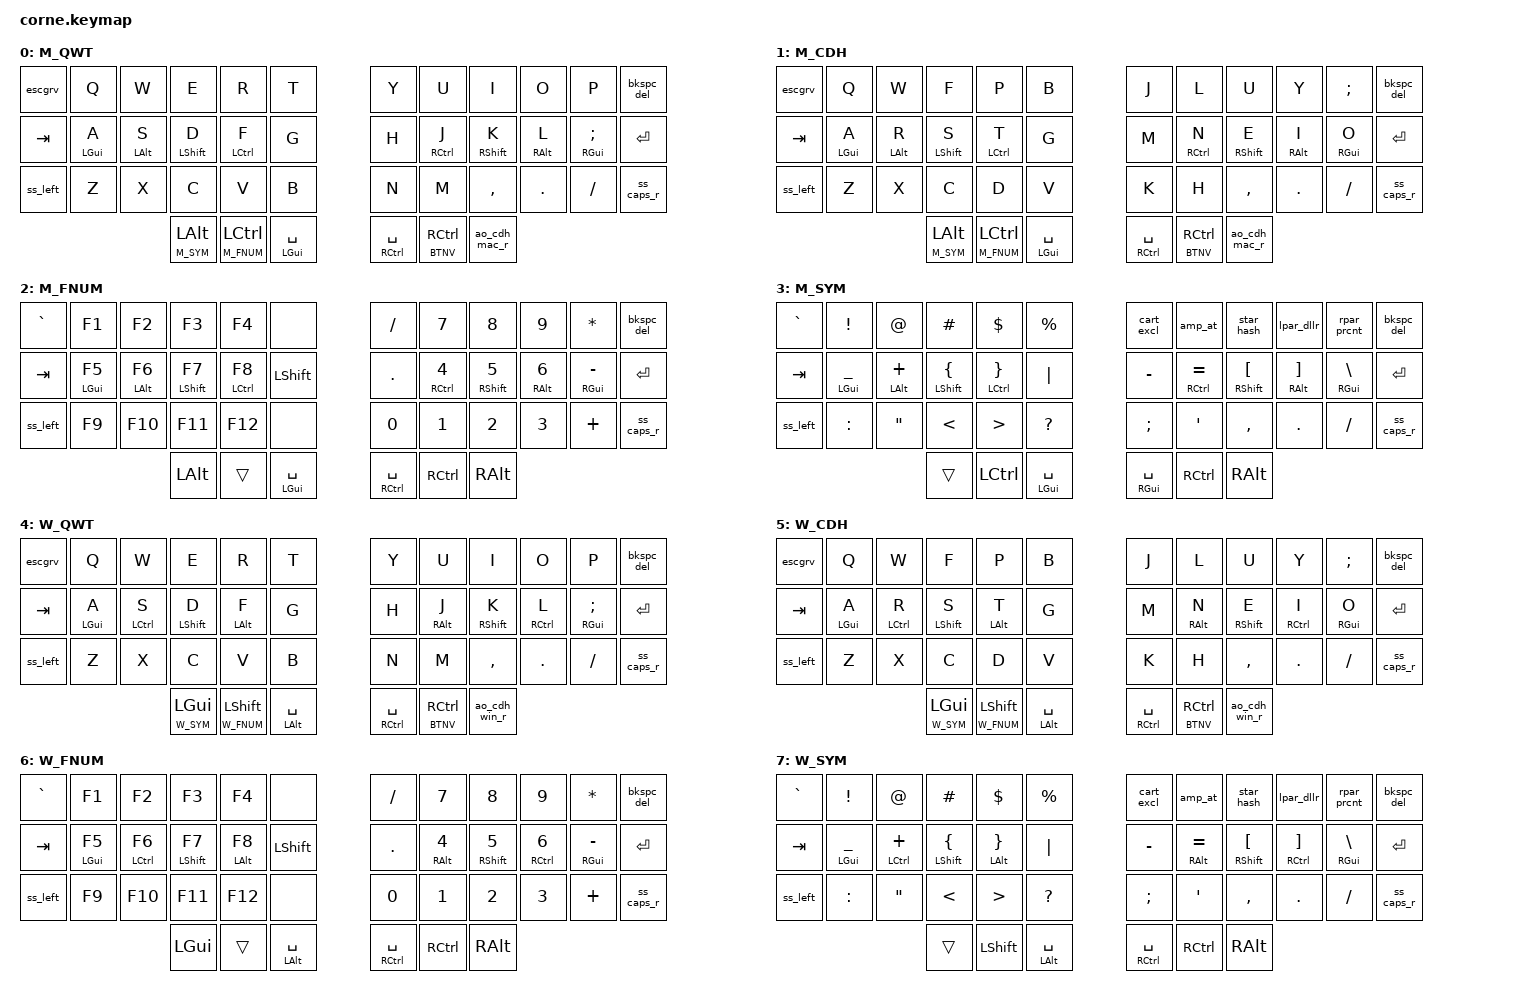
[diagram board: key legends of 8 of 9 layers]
/*
 * Copyright (c) 2020 The ZMK Contributors
 *
 * SPDX-License-Identifier: MIT
 */

// INCLUDES - START  ***********************************************************
// ZMK Core Includes
#include <behaviors.dtsi>
#include <dt-bindings/zmk/keys.h>
#include <dt-bindings/zmk/bt.h>
#include <dt-bindings/zmk/outputs.h>

// JINIUS Includes
// Key position includes
#include "corne_42keys.h"
// INCLUDES - ENDS *************************************************************

// DEFINES - START *************************************************************
// DEFINES LAYERS - START ******************************************************
// Layer shotcuts defined for easier identification.
// The order must match in which they are defined below.
#define M_QWT 0
#define M_CDH 1
#define M_FNUM 2
#define M_SYM 3
#define W_QWT 4
#define W_CDH 5
#define W_FNUM 6
#define W_SYM 7
#define BTNV 8
// DEFINES LAYERS - ENDS *******************************************************
// DEFINES BLUETOOTH PROFILE SELECTION - START *********************************
#define BTP0 BT_SEL 0
#define BTP1 BT_SEL 1
#define BTP2 BT_SEL 2
#define BTP3 BT_SEL 3
#define BTP4 BT_SEL 4
// DEFINES BLUETOOTH PROFILE SELECTION - ENDS **********************************

// DEFINES KEY TYPE ALIAS - START **********************************************
#define XXX &none   // To trap the key event in a given layer
#define ___ &trans  // To pass the key event to the next active layer
// DEFINES KEY TYPE ALIAS - ENDS ***********************************************

// DEFINES GLOBAL SETTINGS - START *********************************************
#define TAPPING_TERM_MS 280
#define QUICK_TAP_MS 175
#define REQUIRE_PRIOR_IDLE_MS 125
// DEFINES GLOBAL SETTINGS - ENDS **********************************************

// DEFINES KEY CONFIGURATION SETTINGS - START **********************************
&sk {  // sticky-key config
    release-after-ms = <900>;  // release after 0.6s
    quick-release;             // no double capitalization when rolling keys
};

&sl {  // sticky-layer config
    ignore-modifiers;          // allow chording sticky mods & layers
};

&lt {  // layer-tap config
    flavor = "balanced";
    tapping-term-ms = <200>;
    quick-tap-ms = <QUICK_TAP_MS>;
};
// DEFINES KEY CONFIGURATION SETTINGS - ENDS ***********************************

// DEFINES COMBINATION KEYS FOR HOMEROW MODS - START ***************************
#define LEFT_HAND_KEYS LT0 LT1 LT2 LT3 LT4 LT5 LM0 LM1 LM2 LM3 LM4 LM5 LB0 LB1 LB2 LB3 LB4 LB5
#define RIGHT_HAND_KEYS RT0 RT1 RT2 RT3 RT4 RT5 RM0 RM1 RM2 RM3 RM4 RM5 RB0 RB1 RB2 RB3 RB4 RB5
#define THUMB_KEYS LH0 LH1 LH2 RH0 RH1 RH2
// DEFINES COMBINATION KEYS FOR HOMEROW MODS - ENDS ****************************

// DEFINES - ENDS **************************************************************

// ROOT DEVICETREE NODE - START ************************************************
/ {

// BEHAVIOR - START ************************************************************
  // BEHAVIOR DEFINITIONS - START **********************************************
  // Homerow mod definition for left hand keys
  behaviors {
    /***********************************************
     **  Homerow mod for left split keyboard
     **  as explained here: https://github.com/urob/zmk-config#timeless-homerow-mods
     **  This is a expanded version of the same functionality along with the timings
     ***********************************************/
    hml: homerow_mod_left {
      compatible = "zmk,behavior-hold-tap";
      #binding-cells = <2>;
      bindings = <&kp>, <&kp>;
      flavor = "balanced";
      tapping-term-ms = <TAPPING_TERM_MS>;
      quick-tap-ms = <QUICK_TAP_MS>;
      require-prior-idle-ms = <REQUIRE_PRIOR_IDLE_MS>;
      hold-trigger-key-positions = <RIGHT_HAND_KEYS THUMB_KEYS>;
    };
    /***********************************************
     **  Homerow mod for right split keyboard
     **  as explained here: https://github.com/urob/zmk-config#timeless-homerow-mods
     **  This is a expanded version of the same functionality along with the timings
     ***********************************************/
    hmr: homerow_mod_right {
      compatible = "zmk,behavior-hold-tap";
      #binding-cells = <2>;
      bindings = <&kp>, <&kp>;
      flavor = "balanced";
      tapping-term-ms = <TAPPING_TERM_MS>;
      quick-tap-ms = <QUICK_TAP_MS>;
      require-prior-idle-ms = <REQUIRE_PRIOR_IDLE_MS>;
      hold-trigger-key-positions = <LEFT_HAND_KEYS THUMB_KEYS>;
    };
    /***********************************************
     ** Momentary Sticky Mod: Momentary layer on hold and tap to sticky modifier
     ** Holding the key will switch to the layer, taping will configure the sticky modifier
     **   hold: momentary layer
     **   tap: sticky modifier
     ***********************************************/
    mosm: momentary_sticky_mod {
      compatible = "zmk,behavior-hold-tap";
      #binding-cells = <2>;
      bindings = <&mo>, <&sk>;
      flavor = "balanced";
      tapping-term-ms = <TAPPING_TERM_MS>;
      quick-tap-ms = <QUICK_TAP_MS>;
      require-prior-idle-ms = <REQUIRE_PRIOR_IDLE_MS>;
      hold-trigger-on-release;
    };
    /***********************************************
     ** Thumb Mod Tap: Hold to modifier, Tap to key press
     ** Holding the key will activate the modifier and tapping activates key press
     **   hold: Modifier
     **   tap: key-press
     ***********************************************/
    tmt: thumb_mod_tap {
      compatible = "zmk,behavior-hold-tap";
      #binding-cells = <2>;
      bindings = <&kp>, <&kp>;
      flavor = "balanced";
      tapping-term-ms = <TAPPING_TERM_MS>;
      quick-tap-ms = <QUICK_TAP_MS>;
      require-prior-idle-ms = <REQUIRE_PRIOR_IDLE_MS>;
      hold-trigger-on-release;
    };
    /***********************************************
     **  Smart Shift Key: As explained here: https://github.com/minusfive/zmk-config#smart-shift
     **  This configuration is for the left split keyboard
     **  Similar setup is defined for the right split keyboard
     **     hold: shift
     **     tap: sticky shift
     **     double-tap: caps-word
     ***********************************************/
    ss_left: smart_shift_left {
      compatible = "zmk,behavior-mod-morph";
      #binding-cells = <0>;
      bindings = <&sk LSHFT>, <&caps_word>;
      mods = <(MOD_LSFT)>;
    };
    /***********************************************
     **  CONTROL LAYER COLEMAKDH: On the right key board
     **     hold: shift
     **     tap: sticky key control
     **     double tap: caps-word
     **     triple tap: caps lock
     ***********************************************/
    ss_caps_r: smart_shift_capslock_right {
      compatible = "zmk,behavior-tap-dance";
      #binding-cells = <0>;
      tapping-term-ms = <200>;
      bindings = <&sk RSHFT>, <&caps_word>, <&kp CAPSLOCK>;
    };
    /***********************************************
     **  Backspace Delete: As defined here: https://github.com/minusfive/zmk-config/blob/main/knucklehead/behaviors.dtsi
     **     tap: backspace
     **     hold: repeat backspace
     **     shift + tap: delete
     **     shift + hold: repeat delete
     ***********************************************/
    bkspc_del: backspace_delete {
      compatible = "zmk,behavior-mod-morph";
      #binding-cells = <0>;
      bindings = <&kp BACKSPACE>, <&kp DELETE>;
      mods = <(MOD_LSFT|MOD_RSFT)>;
    };
    /***********************************************
     **  ESC Grave:
     **     tap: ESCAPE (ESC)
     **     hold: repeat ESCAPE (ESC)
     **     gui/command + tap: command + grave (~)
     **     gui/command + : repeat command + grave (~)
     ***********************************************/
    escgrv: escape_grave {
      compatible = "zmk,behavior-mod-morph";
      #binding-cells = <0>;
      bindings = <&kp ESC>, <&kp GRAVE>;
      mods = <(MOD_LGUI|MOD_RGUI)>;
      keep-mods = <(MOD_LGUI|MOD_RGUI)>;
    };
    /***********************************************
     **  Caret Exclamation:
     **     tap: caret (^)
     **     hold: repeat caret (^)
     **     shift + tap: exclamation (!)
     **     shift + hold: repeat exclamation (!)
     ***********************************************/
    cart_excl: caret_exclamation {
      compatible = "zmk,behavior-mod-morph";
      #binding-cells = <0>;
      bindings = <&kp CARET>, <&kp EXCL>;
      mods = <(MOD_LSFT|MOD_RSFT)>;
    };
    /***********************************************
     **  At Ampersand:
     **     tap: ampersand (&)
     **     hold: repeat ampersand (&)
     **     shift + tap: at (@)
     **     shift + hold: repeat at (@)
     ***********************************************/
    amp_at: ampersand_at {
      compatible = "zmk,behavior-mod-morph";
      #binding-cells = <0>;
      bindings = <&kp AMPS>, <&kp AT>;
      mods = <(MOD_LSFT|MOD_RSFT)>;
    };
    /***********************************************
     **  Star Hash:
     **     tap: star (*)
     **     hold: repeat star (*)
     **     shift + tap: hash (#)
     **     shift + hold: repeat hash (#)
     ***********************************************/
    star_hash: star_hash {
      compatible = "zmk,behavior-mod-morph";
      #binding-cells = <0>;
      bindings = <&kp STAR>, <&kp HASH>;
      mods = <(MOD_LSFT|MOD_RSFT)>;
    };
    /***********************************************
     **  Left Parenthesis Dollar:
     **     tap: left parenthesis (()
     **     hold: repeat left parenthesis (()
     **     shift + tap: dollar ($)
     **     shift + hold: repeat dollar ($)
     ***********************************************/
    lpar_dllr: l_parenthesis_dollar {
      compatible = "zmk,behavior-mod-morph";
      #binding-cells = <0>;
      bindings = <&kp LPAR>, <&kp DOLLAR>;
      mods = <(MOD_LSFT|MOD_RSFT)>;
    };
    /***********************************************
     **  Right Parenthesis Percent:
     **     tap: right parenthesis ())
     **     hold: repeat right parenthesis ())
     **     shift + tap: percent (%)
     **     shift + hold: repeat percent (%)
     ***********************************************/
    rpar_prcnt: r_parenthesis_percent {
      compatible = "zmk,behavior-mod-morph";
      #binding-cells = <0>;
      bindings = <&kp RPAR>, <&kp PERCENT>;
      mods = <(MOD_LSFT|MOD_RSFT)>;
    };
    /***********************************************
     **  ALT/OPT LAYER COLEMAKDH - MAC: On the right key board
     **     tap: sticky key alt/opt
     **     hold: alt/opt
     **     double tap: toggle layer to Colemak-mDH - Mac
     ***********************************************/
    ao_cdh_mac_r: alt_opt_cdh_mac_right {
      compatible = "zmk,behavior-mod-morph";
      #binding-cells = <0>;
      bindings = <&sk RALT>, <&tog M_CDH>;
      mods = <(MOD_RALT)>;
    };
    /***********************************************
     **  ALT/OPT LAYER COLEMAKDH - WIN: On the right key board
     **     tap: sticky key alt/opt
     **     hold: alt/opt
     **     double tap: toggle layer to Colemak-mDH - Win
     ***********************************************/
    ao_cdh_win_r: alt_opt_cdh_win_right {
      compatible = "zmk,behavior-mod-morph";
      #binding-cells = <0>;
      bindings = <&sk RALT>, <&tog W_CDH>;
      mods = <(MOD_RALT)>;
    };
  };
  // BEHAVIOR DEFINITIONS - END ************************************************
// BEHAVIOR - ENDS *************************************************************


// MACROS - START **************************************************************
  // MACROS DEFINITIONS - START ************************************************
  macros {
    mac_bt: mac_bt {
      compatible = "zmk,behavior-macro";
      #binding-cells = <0>;
      bindings = <&macro_tap &bt BTP0>, <&macro_tap &tog M_QWT>;
    };

    win_bt: win_bt {
      compatible = "zmk,behavior-macro";
      #binding-cells = <0>;
      bindings = <&macro_tap &bt BTP4>, <&macro_tap &tog W_QWT>;
    };

    mac_bt_p: mac_bt_p {
      compatible = "zmk,behavior-macro-one-param";
      #binding-cells = <1>;
      bindings = <&macro_param_1to1>, <&macro_tap &bt BT_SEL MACRO_PLACEHOLDER>, <&macro_tap &tog M_QWT>;
    };

    win_bt_p: win_bt_p {
      compatible = "zmk,behavior-macro-one-param";
      #binding-cells = <1>;
      bindings = <&macro_param_1to1>, <&macro_tap &bt BT_SEL MACRO_PLACEHOLDER>, <&macro_tap &tog W_QWT>;
    };
  };
  // MACROS DEFINITIONS - END **************************************************
// MACROS - END ****************************************************************



// KEYMAP NODE - START *********************************************************
  keymap {
    compatible = "zmk,keymap";
    // LAYERS - START **********************************************************
    // QWERTY layer - For Mac
    qwerty_layer_mac {
      display-name = "M_QWT";
      bindings = <
// ╭────-──────────┬───────────────┬───────────────┬───────────────┬───────────────┬───────────────╮   ╭───────────────┬───────────────┬───────────────┬───────────────┬───────────────┬───────────────╮
// ├─   0 <LT5>   ─┼─   1 <LT4>   ─┼─   2 <LT3>   ─┼─   3 <LT2>   ─┼─   4 <LT1>   ─┼─   5 <LT0>   ─┤   ├─   6 <RT0>   ─┼─   7 <RT1>   ─┼─   8 <RT2>   ─┼─   9 <RT3>   ─┼─  10 <RT4>   ─┼─  11 <RT5>   ─┤
// ├─   ESC / ~   ─┼─      Q      ─┼─      W      ─┼─      E      ─┼─      R      ─┼─      T      ─┤   ├─      Y      ─┼─      U      ─┼─      I      ─┼─      O      ─┼─      P      ─┼─ <BKSPC/DEL> ─┤
        &escgrv           &kp Q           &kp W           &kp E           &kp R           &kp T              &kp Y            &kp U           &kp I           &kp O           &kp P        &bkspc_del
// ├─────-─────────├───────────────┼───────────────┼───────────────┼───────────────┼───────────────┤   ├───────────────├───────────────┼───────────────┼───────────────┼───────────────┼───────────────┤
// ├─  12 <LM5>   ─┼─  13 <LM4>   ─┼─  14 <LM3>   ─┼─  15 <LM2>   ─┼─  16 <LM1>   ─┼─  17 <LM0>   ─┤   ├─  18 <RM0>   ─┼─  19 <RM1>   ─┼─  20 <RM2>   ─┼─  21 <RM3>   ─┼─  22 <RM4>   ─┼─  23 <RM5>   ─┤
// ├─     TAB     ─┼─   LGUI / A  ─┼─  LALT / S   ─┼─  LSHFT / D  ─┼─  LCTRL / F  ─┼─      G      ─┤   ├─      H      ─┼─  RCTRL / J  ─┼─ RSHFT / K   ─┼─  RALT / L   ─┼─  RGUI / ;   ─┼─    RETURN   ─┤
        &kp TAB       &hml LGUI A     &hml LALT S    &hml LSHIFT D    &hml LCTRL F       &kp G               &kp H        &hmr RCTRL J   &hmr RSHFT K    &hmr RALT L    &hmr RGUI SEMI      &kp RET
// ├───────────────├───────────────┼───────────────┼───────────────┼───────────────┼───────────────┤   ├───────────────├───────────────┼───────────────┼───────────────┼───────────────┼───────────────┤
// ├─  24 <LB5>   ─┼─  25 <LB4>   ─┼─  26 <LB3>   ─┼─  27 <LB2>   ─┼─  28 <LB1>   ─┼─  29 <LB0>   ─┤   ├─  30 <RB0>   ─┼─  31 <RB1>   ─┼─  32 <RB2>   ─┼─  33 <RB3>   ─┼─  34 <RB4>   ─┼─  35 <RB5>   ─┤
// ├─ SMART SHIFT ─┼─      Z      ─┼─      X      ─┼─      C      ─┼─      V      ─┼─      B      ─┤   ├─      N      ─┼─      M      ─┼─      ,      ─┼─      .      ─┼─      /      ─┼─ SMART SHIFT ─┤
       &ss_left          &kp Z           &kp X           &kp C           &kp V           &kp B               &kp N           &kp M         &kp COMMA        &kp DOT        &kp FSLH        &ss_caps_r
// ╰───────────────┴───────────────┴───────────────┼───────────────┼───────────────┼───────────────┤   ├───────────────├───────────────┼───────────────┼───────────────┴───────────────┴───────────────╯
//                                                 ├─  36 <LH2>   ─┼─  37 <LH1>   ─┼─  38 <LH0>   ─┤   ├─  39 <RH0>   ─┼─  40 <RH1>   ─┼─  41 <RH2>   ─┤
//                                                 ├─ ALT/OPT/SYM ─┼─  CTRL/FNUM  ─┼─   SPC/CMD   ─┤   ├─  SPC/CTRL   ─┼─  CTRL/BTNV  ─┼─ ALT/OPT/CDH ─┤
                                                  &mosm M_SYM LALT &mosm M_FNUM LCTRL &tmt LGUI SPACE &tmt RCTRL SPACE &mosm BTNV RCTRL  &ao_cdh_mac_r
//                                                 ╰───────────────┴───────────────┴───────────────╯   ╰───────────────┴───────────────┴───────────────╯
      >;
    };

    // Colemak Mod-DH - For Mac: Primary layer. To learn and and use
    colemakdh_layer_mac {
      display-name = "M_CDH";
      bindings = <
// ╭───────────────┬───────────────┬───────────────┬───────────────┬───────────────┬───────────────╮   ╭───────────────┬───────────────┬───────────────┬───────────────┬───────────────┬───────────────╮
// ├─   0 <LT5>   ─┼─   1 <LT4>   ─┼─   2 <LT3>   ─┼─   3 <LT2>   ─┼─   4 <LT1>   ─┼─   5 <LT0>   ─┤   ├─   6 <RT0>   ─┼─   7 <RT1>   ─┼─   8 <RT2>   ─┼─   9 <RT3>   ─┼─  10 <RT4>   ─┼─  11 <RT5>   ─┤
// ├─   ESC / ~   ─┼─      Q      ─┼─      W      ─┼─      F      ─┼─      P      ─┼─      B      ─┤   ├─      J      ─┼─      L      ─┼─      U      ─┼─      Y      ─┼─      ;      ─┼─ <BKSPC/DEL> ─┤
        &escgrv          &kp Q           &kp W           &kp F           &kp P           &kp B              &kp J            &kp L           &kp U           &kp Y         &kp SEMI       &bkspc_del
// ├───────────────├───────────────┼───────────────┼───────────────┼───────────────┼───────────────┤   ├───────────────├───────────────┼───────────────┼───────────────┼───────────────┼───────────────┤
// ├─  12 <LM5>   ─┼─  13 <LM4>   ─┼─  14 <LM3>   ─┼─  15 <LM2>   ─┼─  16 <LM1>   ─┼─  17 <LM0>   ─┤   ├─  18 <RM0>   ─┼─  19 <RM1>   ─┼─  20 <RM2>   ─┼─  21 <RM3>   ─┼─  22 <RM4>   ─┼─  23 <RM5>   ─┤
// ├─     TAB     ─┼─   LGUI / A  ─┼─  LALT / R   ─┼─  LSHFT / S  ─┼─  LCTRL / T  ─┼─      G      ─┤   ├─      M      ─┼─  RCTRL / N  ─┼─ RSHFT / E   ─┼─  RALT / I   ─┼─  RGUI / O   ─┼─    RETURN   ─┤
        &kp TAB       &hml LGUI A     &hml LALT R    &hml LSHIFT S    &hml LCTRL T       &kp G               &kp M        &hmr RCTRL N   &hmr RSHFT E     &hmr RALT I     &hmr RGUI O       &kp RET
// ├───────────────├───────────────┼───────────────┼───────────────┼───────────────┼───────────────┤   ├───────────────├───────────────┼───────────────┼───────────────┼───────────────┼───────────────┤
// ├─  24 <LB5>   ─┼─  25 <LB4>   ─┼─  26 <LB3>   ─┼─  27 <LB2>   ─┼─  28 <LB1>   ─┼─  29 <LB0>   ─┤   ├─  30 <RB0>   ─┼─  31 <RB1>   ─┼─  32 <RB2>   ─┼─  33 <RB3>   ─┼─  34 <RB4>   ─┼─  35 <RB5>   ─┤
// ├─ SMART SHIFT ─┼─      z      ─┼─      x      ─┼─      C      ─┼─      D      ─┼─      V      ─┤   ├─      K      ─┼─      H      ─┼─      ,      ─┼─      .      ─┼─      /      ─┼─ SMART SHIFT ─┤
       &ss_left         &kp Z           &kp X           &kp C           &kp D            &kp V               &kp K           &kp H         &kp COMMA        &kp DOT        &kp FSLH        &ss_caps_r
// ╰───────────────┴───────────────┴───────────────┼───────────────┼───────────────┼───────────────┤   ├───────────────├───────────────┼───────────────┼───────────────┴───────────────┴───────────────╯
//                                                 ├─  36 <LH2>   ─┼─  37 <LH1>   ─┼─  38 <LH0>   ─┤   ├─  39 <RH0>   ─┼─  40 <RH1>   ─┼─  41 <RH2>   ─┤
//                                                 ├─ ALT/OPT/SYM ─┼─  CTRL/FNUM  ─┼─   SPC/CMD   ─┤   ├─  SPC/CTRL   ─┼─  CTRL/BTNV  ─┼─ ALT/OPT/CDH ─┤
                                                   &mosm M_SYM LALT &mosm M_FNUM LCTRL &tmt LGUI SPACE &tmt RCTRL SPACE &mosm BTNV RCTRL &ao_cdh_mac_r
//                                                 ╰───────────────┴───────────────┴───────────────╯   ╰───────────────┴───────────────┴───────────────╯
      >;
    };

    // Function and Number layer - For Mac
    function_number_layer_mac {
      display-name = "M_FNUM";
      bindings = <
// ╭───────────────┬───────────────┬───────────────┬───────────────┬───────────────┬───────────────╮   ╭───────────────┬───────────────┬───────────────┬───────────────┬───────────────┬───────────────╮
// ├─   0 <LT5>   ─┼─   1 <LT4>   ─┼─   2 <LT3>   ─┼─   3 <LT2>   ─┼─   4 <LT1>   ─┼─   5 <LT0>   ─┤   ├─   6 <RT0>   ─┼─   7 <RT1>   ─┼─   8 <RT2>   ─┼─   9 <RT3>   ─┼─  10 <RT4>   ─┼─  11 <RT5>   ─┤
// ├─    ` / ~    ─┼─      F1     ─┼─      F2     ─┼─      F3     ─┼─      F4     ─┼─     NONE    ─┤   ├─      /      ─┼─       7     ─┼─       8     ─┼─       9     ─┼─       *     ─┼─ <BKSPC/DEL> ─┤
       &kp GRAVE        &kp F1          &kp F2          &kp F3          &kp F4            XXX             &kp FSLH         &kp N7          &kp N8          &kp N9          &kp STAR        &bkspc_del
// ├───────────────├───────────────┼───────────────┼───────────────┼───────────────┼───────────────┤   ├───────────────├───────────────┼───────────────┼───────────────┼───────────────┼───────────────┤
// ├─  12 <LM5>   ─┼─  13 <LM4>   ─┼─  14 <LM3>   ─┼─  15 <LM2>   ─┼─  16 <LM1>   ─┼─  17 <LM0>   ─┤   ├─  18 <RM0>   ─┼─  19 <RM1>   ─┼─  20 <RM2>   ─┼─  21 <RM3>   ─┼─  22 <RM4>   ─┼─  23 <RM5>   ─┤
// ├─     TAB     ─┼─  LGUI / F5  ─┼─  LALT / F6  ─┼─  LSHFT / F7 ─┼─  LCTRL / F8 ─┼─    LSHFT    ─┤   ├─      .      ─┼─  RCTRL / 4  ─┼─  RSHFT / 5  ─┼─   RALT / 6  ─┼─   RGUI / -  ─┼─    RETURN   ─┤
        &kp TAB       &hml LGUI F5    &hml LALT F6   &hml LSHFT F7   &hml LCTRL F8     &kp LSHFT           &kp DOT       &hmr RCTRL N4   &hmr RSHFT N5   &hmr RALT N6   &hmr RGUI MINUS      &kp RET
// ├───────────────├───────────────┼───────────────┼───────────────┼───────────────┼───────────────┤   ├───────────────├───────────────┼───────────────┼───────────────┼───────────────┼───────────────┤
// ├─  24 <LB5>   ─┼─  25 <LB4>   ─┼─  26 <LB3>   ─┼─  27 <LB2>   ─┼─  28 <LB1>   ─┼─  29 <LB0>   ─┤   ├─  30 <RB0>   ─┼─  31 <RB1>   ─┼─  32 <RB2>   ─┼─  33 <RB3>   ─┼─  34 <RB4>   ─┼─  35 <RB5>   ─┤
// ├─ SMART SHIFT ─┼─      F9     ─┼─     F10     ─┼─      F11    ─┼─      F12    ─┼─     NONE    ─┤   ├─      0      ─┼─      1      ─┼─      2      ─┼─      3      ─┼─      +      ─┼─ SMART SHIFT ─┤
       &ss_left         &kp F9          &kp F10         &kp F11          &kp F12          XXX               &kp N0          &kp N1          &kp N2          &kp N3          &kp PLUS       &ss_caps_r
// ╰───────────────┴───────────────┴───────────────┼───────────────┼───────────────┼───────────────┤   ├───────────────├───────────────┼───────────────┼───────────────┴───────────────┴───────────────╯
//                                                 ├─  36 <LH2>   ─┼─  37 <LH1>   ─┼─  38 <LH0>   ─┤   ├─  39 <RH0>   ─┼─  40 <RH1>   ─┼─  41 <RH2>   ─┤
//                                                 ├─   ALT/OPT   ─┼─    ___      ─┼─   SPC/CMD   ─┤   ├─  SPC/CTRL   ─┼─    CTRL     ─┼─   ALT/OPT   ─┤
                                                       &kp LALT          ___        &tmt LGUI SPACE     &tmt RCTRL SPACE   &kp RCTRL       &kp RALT
//                                                 ╰───────────────┴───────────────┴───────────────╯   ╰───────────────┴───────────────┴───────────────╯
      >;
    };

    // Symbols layer - For Mac
    symbols_layer_mac {
      display-name = "M_SYM";
      bindings = <
// ╭───────────────┬───────────────┬───────────────┬───────────────┬───────────────┬───────────────╮   ╭───────────────┬───────────────┬───────────────┬───────────────┬───────────────┬───────────────╮
// ├─   0 <LT5>   ─┼─   1 <LT4>   ─┼─   2 <LT3>   ─┼─   3 <LT2>   ─┼─   4 <LT1>   ─┼─   5 <LT0>   ─┤   ├─   6 <RT0>   ─┼─   7 <RT1>   ─┼─   8 <RT2>   ─┼─   9 <RT3>   ─┼─  10 <RT4>   ─┼─  11 <RT5>   ─┤
// ├─    ` / ~    ─┼─      !      ─┼─      @      ─┼─      #      ─┼─      $      ─┼─      %      ─┤   ├─    ! / ^    ─┼─    @ / &    ─┼─    # / *    ─┼─    $ / (    ─┼─    % / )    ─┼─ <BKSPC/DEL> ─┤
       &kp GRAVE       &kp EXCL         &kp AT         &kp HASH        &kp DLLR        &kp PRCNT           &cart_excl       &amp_at        &star_hash      &lpar_dllr     &rpar_prcnt      &bkspc_del
// ├───────────────├───────────────┼───────────────┼───────────────┼───────────────┼───────────────┤   ├───────────────├───────────────┼───────────────┼───────────────┼───────────────┼───────────────┤
// ├─  12 <LM5>   ─┼─  13 <LM4>   ─┼─  14 <LM3>   ─┼─  15 <LM2>   ─┼─  16 <LM1>   ─┼─  17 <LM0>   ─┤   ├─  18 <RM0>   ─┼─  19 <RM1>   ─┼─  20 <RM2>   ─┼─  21 <RM3>   ─┼─  22 <RM4>   ─┼─  23 <RM5>   ─┤
// ├─     TAB     ─┼─  LGUI / _   ─┼─  LALT / +   ─┼─  LSHFT / {  ─┼─  LCTRL / }  ─┼─      |      ─┤   ├─    - / _    ─┼─RCTRL / = / +─┼─RSHFT / [ / {─┼─ RALT / ] / }─┼─ RGUI / \ / |─┼─    RETURN   ─┤
        &kp TAB     &hml LGUI UNDER  &hml LALT PLUS &hml LSHFT LBRC &hml LCTRL RBRC    &kp PIPE           &kp MINUS    &hmr RCTRL EQUAL &hmr RSHFT LBKT  &hmr RALT RBKT  &hmr RGUI BSLH     &kp RET
// ├───────────────├───────────────┼───────────────┼───────────────┼───────────────┼───────────────┤   ├───────────────├───────────────┼───────────────┼───────────────┼───────────────┼───────────────┤
// ├─  24 <LB5>   ─┼─  25 <LB4>   ─┼─  26 <LB3>   ─┼─  27 <LB2>   ─┼─  28 <LB1>   ─┼─  29 <LB0>   ─┤   ├─  30 <RB0>   ─┼─  31 <RB1>   ─┼─  32 <RB2>   ─┼─  33 <RB3>   ─┼─  34 <RB4>   ─┼─  35 <RB5>   ─┤
// ├─ SMART SHIFT ─┼─      :      ─┼─      "      ─┼─      <      ─┼─      >      ─┼─      ?      ─┤   ├─    ; / :    ─┼─    ' / "    ─┼─    , / <    ─┼─    . / >    ─┼─   / / ?     ─┼─ SMART SHIFT ─┤
       &ss_left        &kp COLON        &kp DQT         &kp LT          &kp GT         &kp QMARK           &kp SEMI         &kp SQT        &kp COMMA        &kp DOT        &kp FSLH        &ss_caps_r
// ╰───────────────┴───────────────┴───────────────┼───────────────┼───────────────┼───────────────┤   ├───────────────├───────────────┼───────────────┼───────────────┴───────────────┴───────────────╯
//                                                 ├─  36 <LH2>   ─┼─  37 <LH1>   ─┼─  38 <LH0>   ─┤   ├─  39 <RH0>   ─┼─  40 <RH1>   ─┼─  41 <RH2>   ─┤
//                                                 ├─     ___     ─┼─     CTRL    ─┼─     CMD     ─┤   ├─ SPC/CMD/FN  ─┼─     CTRL    ─┼─   ALT/OPT   ─┤
                                                          ___          &kp LCTRL    &tmt LGUI SPACE     &tmt RGUI SPACE    &kp RCTRL       &kp RALT
//                                                 ╰───────────────┴───────────────┴───────────────╯   ╰───────────────┴───────────────┴───────────────╯
      >;
    };

    // QWERTY layer - For WIN
    qwerty_layer_win {
      display-name = "W_QWT";
      bindings = <
// ╭────-──────────┬───────────────┬───────────────┬───────────────┬───────────────┬───────────────╮   ╭───────────────┬───────────────┬───────────────┬───────────────┬───────────────┬───────────────╮
// ├─   0 <LT5>   ─┼─   1 <LT4>   ─┼─   2 <LT3>   ─┼─   3 <LT2>   ─┼─   4 <LT1>   ─┼─   5 <LT0>   ─┤   ├─   6 <RT0>   ─┼─   7 <RT1>   ─┼─   8 <RT2>   ─┼─   9 <RT3>   ─┼─  10 <RT4>   ─┼─  11 <RT5>   ─┤
// ├─   ESC / ~   ─┼─      Q      ─┼─      W      ─┼─      E      ─┼─      R      ─┼─      T      ─┤   ├─      Y      ─┼─      U      ─┼─      I      ─┼─      O      ─┼─      P      ─┼─ <BKSPC/DEL> ─┤
        &escgrv           &kp Q           &kp W           &kp E           &kp R           &kp T              &kp Y            &kp U           &kp I           &kp O           &kp P        &bkspc_del
// ├─────-─────────├───────────────┼───────────────┼───────────────┼───────────────┼───────────────┤   ├───────────────├───────────────┼───────────────┼───────────────┼───────────────┼───────────────┤
// ├─  12 <LM5>   ─┼─  13 <LM4>   ─┼─  14 <LM3>   ─┼─  15 <LM2>   ─┼─  16 <LM1>   ─┼─  17 <LM0>   ─┤   ├─  18 <RM0>   ─┼─  19 <RM1>   ─┼─  20 <RM2>   ─┼─  21 <RM3>   ─┼─  22 <RM4>   ─┼─  23 <RM5>   ─┤
// ├─     TAB     ─┼─   LGUI / A  ─┼─  LCTRL / S  ─┼─  LSHFT / D  ─┼─  LALT / F   ─┼─      G      ─┤   ├─      H      ─┼─  RALT / J   ─┼─ RSHFT / K   ─┼─  RCTRL / L  ─┼─  RGUI / ;   ─┼─    RETURN   ─┤
        &kp TAB       &hml LGUI A    &hml LCTRL S    &hml LSHIFT D    &hml LALT F       &kp G               &kp H         &hmr RALT J    &hmr RSHFT K   &hmr RCTRL L    &hmr RGUI SEMI      &kp RET
// ├───────────────├───────────────┼───────────────┼───────────────┼───────────────┼───────────────┤   ├───────────────├───────────────┼───────────────┼───────────────┼───────────────┼───────────────┤
// ├─  24 <LB5>   ─┼─  25 <LB4>   ─┼─  26 <LB3>   ─┼─  27 <LB2>   ─┼─  28 <LB1>   ─┼─  29 <LB0>   ─┤   ├─  30 <RB0>   ─┼─  31 <RB1>   ─┼─  32 <RB2>   ─┼─  33 <RB3>   ─┼─  34 <RB4>   ─┼─  35 <RB5>   ─┤
// ├─ SMART SHIFT ─┼─      Z      ─┼─      X      ─┼─      C      ─┼─      V      ─┼─      B      ─┤   ├─      N      ─┼─      M      ─┼─      ,      ─┼─      .      ─┼─      /      ─┼─ SMART SHIFT ─┤
       &ss_left          &kp Z           &kp X           &kp C           &kp V           &kp B               &kp N           &kp M         &kp COMMA        &kp DOT        &kp FSLH        &ss_caps_r
// ╰───────────────┴───────────────┴───────────────┼───────────────┼───────────────┼───────────────┤   ├───────────────├───────────────┼───────────────┼───────────────┴───────────────┴───────────────╯
//                                                 ├─  36 <LH2>   ─┼─  37 <LH1>   ─┼─  38 <LH0>   ─┤   ├─  39 <RH0>   ─┼─  40 <RH1>   ─┼─  41 <RH2>   ─┤
//                                                 ├─   WIN/SYM   ─┼─  CTRL/FNUM  ─┼─   ALT/SPC   ─┤   ├─   SPC/CTRL  ─┼─  CTRL/BTNV  ─┼─ ALT/OPT/CDH ─┤
                                                   &mosm W_SYM LGUI &mosm W_FNUM LSHFT &tmt LALT SPACE  &tmt RCTRL SPACE &mosm BTNV RCTRL &ao_cdh_win_r
//                                                 ╰───────────────┴───────────────┴───────────────╯   ╰───────────────┴───────────────┴───────────────╯
      >;
    };

    // Colemak Mod-DH - For WIN: Primary layer. To learn and and use
    colemakdh_layer_win {
      display-name = "W_CDH";
      bindings = <
// ╭───────────────┬───────────────┬───────────────┬───────────────┬───────────────┬───────────────╮   ╭───────────────┬───────────────┬───────────────┬───────────────┬───────────────┬───────────────╮
// ├─   0 <LT5>   ─┼─   1 <LT4>   ─┼─   2 <LT3>   ─┼─   3 <LT2>   ─┼─   4 <LT1>   ─┼─   5 <LT0>   ─┤   ├─   6 <RT0>   ─┼─   7 <RT1>   ─┼─   8 <RT2>   ─┼─   9 <RT3>   ─┼─  10 <RT4>   ─┼─  11 <RT5>   ─┤
// ├─   ESC / ~   ─┼─      Q      ─┼─      W      ─┼─      F      ─┼─      P      ─┼─      B      ─┤   ├─      J      ─┼─      L      ─┼─      U      ─┼─      Y      ─┼─      ;      ─┼─ <BKSPC/DEL> ─┤
        &escgrv          &kp Q           &kp W           &kp F           &kp P           &kp B              &kp J            &kp L           &kp U           &kp Y         &kp SEMI       &bkspc_del
// ├───────────────├───────────────┼───────────────┼───────────────┼───────────────┼───────────────┤   ├───────────────├───────────────┼───────────────┼───────────────┼───────────────┼───────────────┤
// ├─  12 <LM5>   ─┼─  13 <LM4>   ─┼─  14 <LM3>   ─┼─  15 <LM2>   ─┼─  16 <LM1>   ─┼─  17 <LM0>   ─┤   ├─  18 <RM0>   ─┼─  19 <RM1>   ─┼─  20 <RM2>   ─┼─  21 <RM3>   ─┼─  22 <RM4>   ─┼─  23 <RM5>   ─┤
// ├─     TAB     ─┼─   LGUI / A  ─┼─  LCTRL / R  ─┼─  LSHFT / S  ─┼─  LALT / T   ─┼─      G      ─┤   ├─      M      ─┼─  RALT / N   ─┼─ RSHFT / E   ─┼─  RCTRL / I  ─┼─  RGUI / O   ─┼─    RETURN   ─┤
        &kp TAB       &hml LGUI A    &hml LCTRL R    &hml LSHIFT S    &hml LALT T        &kp G               &kp M        &hmr RALT N    &hmr RSHFT E    &hmr RCTRL I     &hmr RGUI O       &kp RET
// ├───────────────├───────────────┼───────────────┼───────────────┼───────────────┼───────────────┤   ├───────────────├───────────────┼───────────────┼───────────────┼───────────────┼───────────────┤
// ├─  24 <LB5>   ─┼─  25 <LB4>   ─┼─  26 <LB3>   ─┼─  27 <LB2>   ─┼─  28 <LB1>   ─┼─  29 <LB0>   ─┤   ├─  30 <RB0>   ─┼─  31 <RB1>   ─┼─  32 <RB2>   ─┼─  33 <RB3>   ─┼─  34 <RB4>   ─┼─  35 <RB5>   ─┤
// ├─ SMART SHIFT ─┼─      z      ─┼─      x      ─┼─      C      ─┼─      D      ─┼─      V      ─┤   ├─      K      ─┼─      H      ─┼─      ,      ─┼─      .      ─┼─      /      ─┼─ SMART SHIFT ─┤
       &ss_left         &kp Z           &kp X           &kp C           &kp D            &kp V               &kp K           &kp H         &kp COMMA        &kp DOT        &kp FSLH        &ss_caps_r
// ╰───────────────┴───────────────┴───────────────┼───────────────┼───────────────┼───────────────┤   ├───────────────├───────────────┼───────────────┼───────────────┴───────────────┴───────────────╯
//                                                 ├─  36 <LH2>   ─┼─  37 <LH1>   ─┼─  38 <LH0>   ─┤   ├─  39 <RH0>   ─┼─  40 <RH1>   ─┼─  41 <RH2>   ─┤
//                                                 ├─   WIN/SYM   ─┼─  LSHFT/FNUM ─┼─   SPC/CMD   ─┤   ├─   SPC/CMD   ─┼─  CTRL/BTNV  ─┼─ ALT/OPT/CDH ─┤
                                                   &mosm W_SYM LGUI &mosm W_FNUM LSHFT &tmt LALT SPACE &tmt RCTRL SPACE &mosm BTNV RCTRL  &ao_cdh_win_r
//                                                 ╰───────────────┴───────────────┴───────────────╯   ╰───────────────┴───────────────┴───────────────╯
      >;
    };

    // Function and Number layer - For WIN
    function_number_layer_win {
      display-name = "W_FNUM";
      bindings = <
// ╭───────────────┬───────────────┬───────────────┬───────────────┬───────────────┬───────────────╮   ╭───────────────┬───────────────┬───────────────┬───────────────┬───────────────┬───────────────╮
// ├─   0 <LT5>   ─┼─   1 <LT4>   ─┼─   2 <LT3>   ─┼─   3 <LT2>   ─┼─   4 <LT1>   ─┼─   5 <LT0>   ─┤   ├─   6 <RT0>   ─┼─   7 <RT1>   ─┼─   8 <RT2>   ─┼─   9 <RT3>   ─┼─  10 <RT4>   ─┼─  11 <RT5>   ─┤
// ├─    ` / ~    ─┼─      F1     ─┼─      F2     ─┼─      F3     ─┼─      F4     ─┼─     NONE    ─┤   ├─      /      ─┼─       7     ─┼─       8     ─┼─       9     ─┼─       *     ─┼─ <BKSPC/DEL> ─┤
       &kp GRAVE        &kp F1          &kp F2          &kp F3          &kp F4            XXX             &kp FSLH         &kp N7          &kp N8          &kp N9          &kp STAR        &bkspc_del
// ├───────────────├───────────────┼───────────────┼───────────────┼───────────────┼───────────────┤   ├───────────────├───────────────┼───────────────┼───────────────┼───────────────┼───────────────┤
// ├─  12 <LM5>   ─┼─  13 <LM4>   ─┼─  14 <LM3>   ─┼─  15 <LM2>   ─┼─  16 <LM1>   ─┼─  17 <LM0>   ─┤   ├─  18 <RM0>   ─┼─  19 <RM1>   ─┼─  20 <RM2>   ─┼─  21 <RM3>   ─┼─  22 <RM4>   ─┼─  23 <RM5>   ─┤
// ├─     TAB     ─┼─  LGUI / F5  ─┼─ LCTRL / F6  ─┼─  LSHFT / F7 ─┼─  LALT / F8  ─┼─    LSHFT    ─┤   ├─      .      ─┼─   RALT / 4  ─┼─  RSHFT / 5  ─┼─  RCTRL / 6  ─┼─   RGUI / -  ─┼─    RETURN   ─┤
        &kp TAB       &hml LGUI F5   &hml LCTRL F6   &hml LSHFT F7    &hml LALT F8     &kp LSHFT           &kp DOT       &hmr RALT N4   &hmr RSHFT N5    &hmr RCTRL N6  &hmr RGUI MINUS      &kp RET
// ├───────────────├───────────────┼───────────────┼───────────────┼───────────────┼───────────────┤   ├───────────────├───────────────┼───────────────┼───────────────┼───────────────┼───────────────┤
// ├─  24 <LB5>   ─┼─  25 <LB4>   ─┼─  26 <LB3>   ─┼─  27 <LB2>   ─┼─  28 <LB1>   ─┼─  29 <LB0>   ─┤   ├─  30 <RB0>   ─┼─  31 <RB1>   ─┼─  32 <RB2>   ─┼─  33 <RB3>   ─┼─  34 <RB4>   ─┼─  35 <RB5>   ─┤
// ├─ SMART SHIFT ─┼─      F9     ─┼─     F10     ─┼─      F11    ─┼─      F12    ─┼─     NONE    ─┤   ├─      0      ─┼─      1      ─┼─      2      ─┼─      3      ─┼─      +      ─┼─ SMART SHIFT ─┤
       &ss_left         &kp F9          &kp F10         &kp F11          &kp F12          XXX               &kp N0          &kp N1          &kp N2          &kp N3          &kp PLUS       &ss_caps_r
// ╰───────────────┴───────────────┴───────────────┼───────────────┼───────────────┼───────────────┤   ├───────────────├───────────────┼───────────────┼───────────────┴───────────────┴───────────────╯
//                                                 ├─  36 <LH2>   ─┼─  37 <LH1>   ─┼─  38 <LH0>   ─┤   ├─  39 <RH0>   ─┼─  40 <RH1>   ─┼─  41 <RH2>   ─┤
//                                                 ├─   ALT/OPT   ─┼─    ___      ─┼─   SPC/CMD   ─┤   ├─   SPC/CMD   ─┼─     CTRL    ─┼─   ALT/OPT   ─┤
                                                       &kp LGUI          ___        &tmt LALT SPACE     &tmt RCTRL SPACE    &kp RCTRL       &kp RALT
//                                                 ╰───────────────┴───────────────┴───────────────╯   ╰───────────────┴───────────────┴───────────────╯
      >;
    };

    // Symbols layer - For WIN
    symbols_layer_win {
      display-name = "W_SYM";
      bindings = <
// ╭───────────────┬───────────────┬───────────────┬───────────────┬───────────────┬───────────────╮   ╭───────────────┬───────────────┬───────────────┬───────────────┬───────────────┬───────────────╮
// ├─   0 <LT5>   ─┼─   1 <LT4>   ─┼─   2 <LT3>   ─┼─   3 <LT2>   ─┼─   4 <LT1>   ─┼─   5 <LT0>   ─┤   ├─   6 <RT0>   ─┼─   7 <RT1>   ─┼─   8 <RT2>   ─┼─   9 <RT3>   ─┼─  10 <RT4>   ─┼─  11 <RT5>   ─┤
// ├─    ` / ~    ─┼─      !      ─┼─      @      ─┼─      #      ─┼─      $      ─┼─      %      ─┤   ├─    ! / ^    ─┼─    @ / &    ─┼─    # / *    ─┼─    $ / (    ─┼─    % / )    ─┼─ <BKSPC/DEL> ─┤
       &kp GRAVE       &kp EXCL         &kp AT         &kp HASH        &kp DLLR        &kp PRCNT           &cart_excl       &amp_at        &star_hash      &lpar_dllr     &rpar_prcnt      &bkspc_del
// ├───────────────├───────────────┼───────────────┼───────────────┼───────────────┼───────────────┤   ├───────────────├───────────────┼───────────────┼───────────────┼───────────────┼───────────────┤
// ├─  12 <LM5>   ─┼─  13 <LM4>   ─┼─  14 <LM3>   ─┼─  15 <LM2>   ─┼─  16 <LM1>   ─┼─  17 <LM0>   ─┤   ├─  18 <RM0>   ─┼─  19 <RM1>   ─┼─  20 <RM2>   ─┼─  21 <RM3>   ─┼─  22 <RM4>   ─┼─  23 <RM5>   ─┤
// ├─     TAB     ─┼─  LGUID / _  ─┼─  LCTRL / +  ─┼─  LSHFT / {  ─┼─   LALT / }  ─┼─      |      ─┤   ├─    - / _    ─┼─ RALT / = / +─┼─RSHFT / [ / {─┼─RCTRL / ] / }─┼─ RGUI / \ / |─┼─    RETURN   ─┤
        &kp TAB     &hml LGUI UNDER &hml LCTRL PLUS &hml LSHFT LBRC &hml LALT RBRC     &kp PIPE           &kp MINUS    &hmr RALT EQUAL  &hmr RSHFT LBKT &hmr RCTRL RBKT  &hmr RGUI BSLH     &kp RET
// ├───────────────├───────────────┼───────────────┼───────────────┼───────────────┼───────────────┤   ├───────────────├───────────────┼───────────────┼───────────────┼───────────────┼───────────────┤
// ├─  24 <LB5>   ─┼─  25 <LB4>   ─┼─  26 <LB3>   ─┼─  27 <LB2>   ─┼─  28 <LB1>   ─┼─  29 <LB0>   ─┤   ├─  30 <RB0>   ─┼─  31 <RB1>   ─┼─  32 <RB2>   ─┼─  33 <RB3>   ─┼─  34 <RB4>   ─┼─  35 <RB5>   ─┤
// ├─ SMART SHIFT ─┼─      :      ─┼─      "      ─┼─      <      ─┼─      >      ─┼─      ?      ─┤   ├─    ; / :    ─┼─    ' / "    ─┼─    , / <    ─┼─    . / >    ─┼─   / / ?     ─┼─ SMART SHIFT ─┤
       &ss_left        &kp COLON        &kp DQT         &kp LT          &kp GT         &kp QMARK           &kp SEMI         &kp SQT        &kp COMMA        &kp DOT        &kp FSLH        &ss_caps_r
// ╰───────────────┴───────────────┴───────────────┼───────────────┼───────────────┼───────────────┤   ├───────────────├───────────────┼───────────────┼───────────────┴───────────────┴───────────────╯
//                                                 ├─  36 <LH2>   ─┼─  37 <LH1>   ─┼─  38 <LH0>   ─┤   ├─  39 <RH0>   ─┼─  40 <RH1>   ─┼─  41 <RH2>   ─┤
//                                                 ├─     ___     ─┼─     LSHFT   ─┼─    LALT     ─┤   ├─ SPC/CTRL/FN ─┼─     CTRL    ─┼─   ALT/OPT   ─┤
                                                          ___          &kp LSHFT    &tmt LALT SPACE     &tmt RCTRL SPACE    &kp RCTRL       &kp RALT
//                                                 ╰───────────────┴───────────────┴───────────────╯   ╰───────────────┴───────────────┴───────────────╯
      >;
    };


    // Bluetooth and Navigation layer
    bt_navigation_layer {
      display-name = "BTNV";
      bindings = <
// ╭───────────────┬───────────────┬───────────────┬───────────────┬───────────────┬───────────────╮   ╭───────────────┬───────────────┬───────────────┬───────────────┬───────────────┬───────────────╮
// ├─   0 <LT5>   ─┼─   1 <LT4>   ─┼─   2 <LT3>   ─┼─   3 <LT2>   ─┼─   4 <LT1>   ─┼─   5 <LT0>   ─┤   ├─   6 <RT0>   ─┼─   7 <RT1>   ─┼─   8 <RT2>   ─┼─   9 <RT3>   ─┼─  10 <RT4>   ─┼─  11 <RT5>   ─┤
// ├─   ESC / ~   ─┼─   OUT USB   ─┼─  BOOTLOADER ─┼─    BT CLR   ─┼─    RESET    ─┼─   OUT BLE   ─┤   ├─     HOME    ─┼─ BTP0 / M_QWT─┼─      UP     ─┼─ BTP4 / W_QWT─┼─    PG UP    ─┼─ <BKSPC/DEL> ─┤
        &escgrv       &out OUT_USB    &bootloader      &bt BT_CLR      &sys_reset     &out OUT_BLE          &kp HOME      &mac_bt_p 0        &kp UP       &win_bt_p 4       &kp PG_UP       &bkspc_del
// ├───────────────├───────────────┼───────────────┼───────────────┼───────────────┼───────────────┤   ├───────────────├───────────────┼───────────────┼───────────────┼───────────────┼───────────────┤
// ├─  12 <LM5>   ─┼─  13 <LM4>   ─┼─  14 <LM3>   ─┼─  15 <LM2>   ─┼─  16 <LM1>   ─┼─  17 <LM0>   ─┤   ├─  18 <RM0>   ─┼─  19 <RM1>   ─┼─  20 <RM2>   ─┼─  21 <RM3>   ─┼─  22 <RM4>   ─┼─  23 <RM5>   ─┤
// ├─     TAB     ─┼─ LGUI / NONE ─┼─ LALT / NONE ─┼─ LSHFT / NONE─┼─ LCTRL / NONE─┼─     NONE    ─┤   ├─     END     ─┼─ RCTRL / LEFT─┼─RSHFT / DOWN ─┼─ RALT / RIGHT─┼─ RGUI / PG DN─┼─    RETURN   ─┤
        &kp TAB      &hml LGUI XXX   &hml LALT XXX   &hml LSHFT XXX  &hml LCTRL XXX       XXX               &kp END     &hmr RCTRL LEFT &hmr RSHFT DOWN &hmr RALT RIGHT  &hmr RGUI PG_DN     &kp RET
// ├───────────────├───────────────┼───────────────┼───────────────┼───────────────┼───────────────┤   ├───────────────├───────────────┼───────────────┼───────────────┼───────────────┼───────────────┤
// ├─  24 <LB5>   ─┼─  25 <LB4>   ─┼─  26 <LB3>   ─┼─  27 <LB2>   ─┼─  28 <LB1>   ─┼─  29 <LB0>   ─┤   ├─  30 <RB0>   ─┼─  31 <RB1>   ─┼─  32 <RB2>   ─┼─  33 <RB3>   ─┼─  34 <RB4>   ─┼─  35 <RB5>   ─┤
// ├─ SMART SHIFT ─┼─     BT0     ─┼─     BT1     ─┼─     BT2     ─┼─    BT3      ─┼─    BT4      ─┤   ├─    W_QWT    ─┼─    BT_WIN   ─┼─  BRIGHT UP  ─┼─  BRIGHT DN  ─┼─   BT_MAC    ─┼─ SMART SHIFT ─┤
       &ss_left       &bt BT_SEL 0    &bt BT_SEL 1   &bt BT_SEL 2    &bt BT_SEL 3    &bt BT_SEL 4          &tog W_QWT       &win_bt       &kp C_BRI_UP    &kp C_BRI_DN      &mac_bt        &ss_caps_r
// ╰───────────────┴───────────────┴───────────────┼───────────────┼───────────────┼───────────────┤   ├───────────────├───────────────┼───────────────┼───────────────┴───────────────┴───────────────╯
//                                                 ├─  36 <LH2>   ─┼─  37 <LH1>   ─┼─  38 <LH0>   ─┤   ├─  39 <RH0>   ─┼─  40 <RH1>   ─┼─  41 <RH2>   ─┤
//                                                 ├─   ALT/OPT   ─┼─     CTRL    ─┼─   SPC/CMD   ─┤   ├─   SPC/CMD   ─┼─     ___     ─┼─   ALT/OPT   ─┤
                                                       &kp LALT        &kp LCTRL    &tmt LGUI SPACE     &tmt RGUI SPACE       ___           &kp RALT
//                                                 ╰───────────────┴───────────────┴───────────────╯   ╰───────────────┴───────────────┴───────────────╯
      >;
    };

// LAYERS - ENDS ***************************************************************
  };
// KEYMAP NODE - ENDS **********************************************************
};
// ROOT DEVICETREE NODE - ENDS *************************************************
